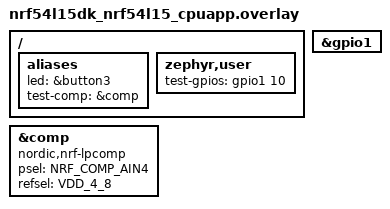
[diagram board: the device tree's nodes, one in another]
/*
 * Copyright (c) 2024 Nordic Semiconductor ASA
 *
 * SPDX-License-Identifier: LicenseRef-Nordic-5-Clause
 */

#include <zephyr/dt-bindings/comparator/nrf-comp.h>

/ {
	aliases {
		led = &button3;
		test-comp = &comp;
	};

	zephyr,user {
		test-gpios = <&gpio1 10 GPIO_ACTIVE_HIGH>;
	};
};

&gpio1 {
	status = "okay";
};

&comp {
	compatible = "nordic,nrf-lpcomp";
	psel = <NRF_COMP_AIN4>; /* P1.11 */
	refsel = "VDD_4_8";
	status = "okay";
};
